# TIMESYNC_EVENT_INTROUTER_INTR_ROUTER_CFG_00A40000h register map
Vendor: Texas Instruments
Peripheral module from a debugger description file (folder AM275x).
Registers are 32-bit, read-only, reset 0x66948100 unless marked. A register's access mark holds for its fields unless they carry their own. Offsets are as the file gives them; lines under a group give offsets from that group; [hi:lo] are bit positions; {n}, {i} and the like mark numbered series; 'fields as' and 'values as' point back to an identical list; <NAME> marks a mode.

## intr_router_cfg
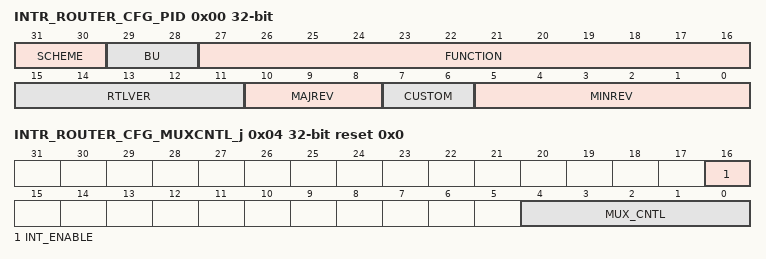
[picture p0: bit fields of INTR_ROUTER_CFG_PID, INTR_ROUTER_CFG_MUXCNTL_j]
0x00 INTR_ROUTER_CFG_PID — Identification register
  [31:30] SCHEME — scheme Reset Source: intr_rst_n
  [29:28] BU — Business Unit Reset Source: intr_rst_n
  [27:16] FUNCTION — function Reset Source: intr_rst_n
  [15:11] RTLVER — rtl version Reset Source: intr_rst_n
  [10:8] MAJREV — major version Reset Source: intr_rst_n
  [7:6] CUSTOM — custom id Reset Source: intr_rst_n
  [5:0] MINREV — minor version Reset Source: intr_rst_n
0x04 INTR_ROUTER_CFG_MUXCNTL_j rw reset 0x0 — Interrupt mux control register
  [16] INT_ENABLE — interrupt output enable for interrupt N Reset Source: intr_rst_n
  [4:0] MUX_CNTL — Mux control for interrupt N Reset Source: intr_rst_n
